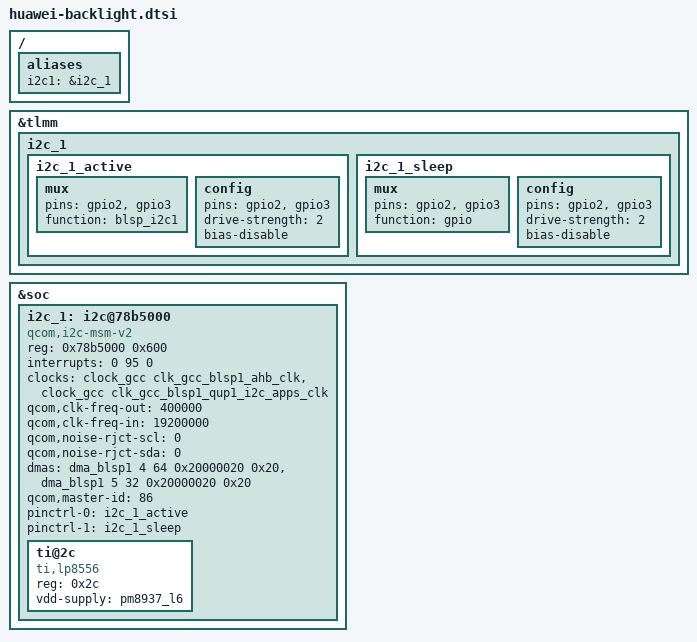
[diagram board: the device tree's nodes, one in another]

/ {
	aliases {
		i2c1 = &i2c_1;
	};
};

&tlmm {
	i2c_1 {
		i2c_1_active: i2c_1_active {
			/* active state */
			mux {
				pins = "gpio2", "gpio3";
				function = "blsp_i2c1";
			};

			config {
				pins = "gpio2", "gpio3";
				drive-strength = <2>;
				bias-disable;
			};
		};

		i2c_1_sleep: i2c_1_sleep {
			/* suspended state */
			mux {
				pins = "gpio2", "gpio3";
				function = "gpio";
			};

			config {
				pins = "gpio2", "gpio3";
				drive-strength = <2>;
				bias-disable;
			};
		};
    };
};

&soc {
    i2c_1: i2c@78b5000 { /* BLSP1 QUP1 */
		compatible = "qcom,i2c-msm-v2";
		#address-cells = <1>;
		#size-cells = <0>;
		reg-names = "qup_phys_addr";
		reg = <0x78b5000 0x600>;
		interrupt-names = "qup_irq";
		interrupts = <0 95 0>;
		clocks = <&clock_gcc clk_gcc_blsp1_ahb_clk>,
			<&clock_gcc clk_gcc_blsp1_qup1_i2c_apps_clk>;
        clock-names = "iface_clk", "core_clk";
        qcom,clk-freq-out = <400000>;
        qcom,clk-freq-in  = <19200000>;
        qcom,noise-rjct-scl = <0>;
        qcom,noise-rjct-sda = <0>;
        dmas = <&dma_blsp1 4 64 0x20000020 0x20>,
            <&dma_blsp1 5  32 0x20000020 0x20>;
        dma-names = "tx", "rx";
        qcom,master-id = <86>;
		status = "disabled";
    };
};

&i2c_1 {
	status = "ok";
    pinctrl-names = "i2c_active", "i2c_sleep";
    pinctrl-0 = <&i2c_1_active>;
    pinctrl-1 = <&i2c_1_sleep>;
	
    ti@2c { /* ti backlight ic*/
		status = "ok";
		compatible = "ti,lp8556";
		reg = <0x2c>;
		vdd-supply = <&pm8937_l6>;
	  };
};

